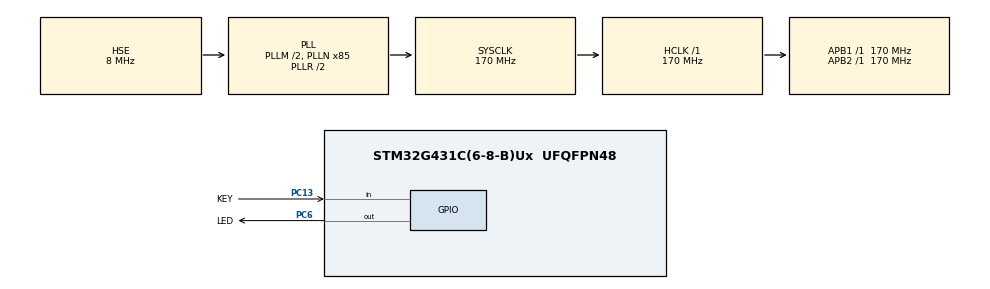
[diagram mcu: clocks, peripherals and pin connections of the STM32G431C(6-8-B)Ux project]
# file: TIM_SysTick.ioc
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Mcu.Family=STM32G4
Mcu.Name=STM32G431C(6-8-B)Ux
Mcu.Package=UFQFPN48
NVIC.PriorityGroup=NVIC_PRIORITYGROUP_4
PA13.Mode=Serial_Wire
PA13.Signal=SYS_JTMS-SWDIO
PA14.Mode=Serial_Wire
PA14.Signal=SYS_JTCK-SWCLK
PC13.GPIO_Label=KEY
PC13.GPIO_PuPd=GPIO_PULLDOWN
PC13.Signal=GPIO_Input
PC6.GPIO_Label=LED
PC6.GPIO_ModeDefaultOutputPP=GPIO_MODE_OUTPUT_PP
PC6.GPIO_Speed=GPIO_SPEED_FREQ_LOW
PC6.PinState=GPIO_PIN_RESET
PC6.Signal=GPIO_Output
PF0-OSC_IN.Mode=HSE-External-Oscillator
PF0-OSC_IN.Signal=RCC_OSC_IN
PF1-OSC_OUT.Mode=HSE-External-Oscillator
PF1-OSC_OUT.Signal=RCC_OSC_OUT
ProjectManager.HeapSize=0x200
ProjectManager.StackSize=0x400
ProjectManager.TargetToolchain=STM32CubeIDE
RCC.ADC12Freq_Value=170000000
RCC.AHBFreq_Value=170000000
RCC.APB1Freq_Value=170000000
RCC.APB1TimFreq_Value=170000000
RCC.APB2Freq_Value=170000000
RCC.APB2TimFreq_Value=170000000
RCC.CortexFreq_Value=170000000
RCC.EXTERNAL_CLOCK_VALUE=12288000
RCC.HCLKFreq_Value=170000000
RCC.HSE_VALUE=8000000
RCC.HSI48_VALUE=48000000
RCC.HSI_VALUE=16000000
RCC.LSE_VALUE=32768
RCC.PLLM=RCC_PLLM_DIV2
RCC.PLLN=85
RCC.PLLSourceVirtual=RCC_PLLSOURCE_HSE
RCC.SYSCLKFreq_VALUE=170000000
RCC.SYSCLKSource=RCC_SYSCLKSOURCE_PLLCLK
RCC.USBFreq_Value=170000000
RCC.VCOOutputFreq_Value=340000000
VP_SYS_VS_DBSignals.Mode=DisableDeadBatterySignals
board=custom

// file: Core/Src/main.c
/* USER CODE BEGIN Header */
/**
  ******************************************************************************
  * @file           : main.c
  * @brief          : Main program body
  ******************************************************************************
  * @attention
  *
  * Copyright (c) 2025 STMicroelectronics.
  * All rights reserved.
  *
  * This software is licensed under terms that can be found in the LICENSE file
  * in the root directory of this software component.
  * If no LICENSE file comes with this software, it is provided AS-IS.
  *
  ******************************************************************************
  */
/* USER CODE END Header */
#include "main.h"

/* USER CODE BEGIN PV */

uint32_t TimeResult = 0;
uint32_t TimeStart = 0;
volatile uint8_t TimeState = 0;

/* USER CODE END PV */

void SystemClock_Config(void);
static void MX_GPIO_Init(void);

int main(void)
{

  /* MCU Configuration--------------------------------------------------------*/

  /* Reset of all peripherals, Initializes the Flash interface and the Systick. */
  HAL_Init();

  /* Configure the system clock */
  SystemClock_Config();

  /* Initialize all configured peripherals */
  MX_GPIO_Init();

  /* Infinite loop */
  /* USER CODE BEGIN WHILE */
  while (1)
  {
	  if (HAL_GPIO_ReadPin(KEY_GPIO_Port, KEY_Pin) == GPIO_PIN_SET) { // If button is pressed
		  if (TimeState == 0) { // If state 0
			  TimeStart = HAL_GetTick();

			  HAL_GPIO_WritePin(LED_GPIO_Port, LED_Pin, GPIO_PIN_SET);
			  TimeState = 1;
		  } else { // TimeState == 1
			  if ((HAL_GetTick() - TimeStart) > 500) { // 0.5 seconds have passed
				  TimeResult = HAL_GetTick() - TimeStart;

				  HAL_GPIO_WritePin(LED_GPIO_Port, LED_Pin, GPIO_PIN_RESET);
				  TimeState = 0;

				  HAL_Delay(500);
			  }
		  }

	  }

    /* USER CODE END WHILE */

  }
}

void SystemClock_Config(void)
{
  RCC_OscInitTypeDef RCC_OscInitStruct = {0};
  RCC_ClkInitTypeDef RCC_ClkInitStruct = {0};

  /** Configure the main internal regulator output voltage
  */
  HAL_PWREx_ControlVoltageScaling(PWR_REGULATOR_VOLTAGE_SCALE1_BOOST);

  /** Initializes the RCC Oscillators according to the specified parameters
  * in the RCC_OscInitTypeDef structure.
  */
  RCC_OscInitStruct.OscillatorType = RCC_OSCILLATORTYPE_HSE;
  RCC_OscInitStruct.HSEState = RCC_HSE_ON;
  RCC_OscInitStruct.PLL.PLLState = RCC_PLL_ON;
  RCC_OscInitStruct.PLL.PLLSource = RCC_PLLSOURCE_HSE;
  RCC_OscInitStruct.PLL.PLLM = RCC_PLLM_DIV2;
  RCC_OscInitStruct.PLL.PLLN = 85;
  RCC_OscInitStruct.PLL.PLLP = RCC_PLLP_DIV2;
  RCC_OscInitStruct.PLL.PLLQ = RCC_PLLQ_DIV2;
  RCC_OscInitStruct.PLL.PLLR = RCC_PLLR_DIV2;
  if (HAL_RCC_OscConfig(&RCC_OscInitStruct) != HAL_OK)
  {
    Error_Handler();
  }

  /** Initializes the CPU, AHB and APB buses clocks
  */
  RCC_ClkInitStruct.ClockType = RCC_CLOCKTYPE_HCLK|RCC_CLOCKTYPE_SYSCLK
                              |RCC_CLOCKTYPE_PCLK1|RCC_CLOCKTYPE_PCLK2;
  RCC_ClkInitStruct.SYSCLKSource = RCC_SYSCLKSOURCE_PLLCLK;
  RCC_ClkInitStruct.AHBCLKDivider = RCC_SYSCLK_DIV1;
  RCC_ClkInitStruct.APB1CLKDivider = RCC_HCLK_DIV1;
  RCC_ClkInitStruct.APB2CLKDivider = RCC_HCLK_DIV1;

  if (HAL_RCC_ClockConfig(&RCC_ClkInitStruct, FLASH_LATENCY_4) != HAL_OK)
  {
    Error_Handler();
  }
}

static void MX_GPIO_Init(void)
{
  GPIO_InitTypeDef GPIO_InitStruct = {0};

  /* GPIO Ports Clock Enable */
  __HAL_RCC_GPIOC_CLK_ENABLE();
  __HAL_RCC_GPIOF_CLK_ENABLE();
  __HAL_RCC_GPIOA_CLK_ENABLE();

  /*Configure GPIO pin Output Level */
  HAL_GPIO_WritePin(LED_GPIO_Port, LED_Pin, GPIO_PIN_RESET);

  /*Configure GPIO pin : KEY_Pin */
  GPIO_InitStruct.Pin = KEY_Pin;
  GPIO_InitStruct.Mode = GPIO_MODE_INPUT;
  GPIO_InitStruct.Pull = GPIO_PULLDOWN;
  HAL_GPIO_Init(KEY_GPIO_Port, &GPIO_InitStruct);

  /*Configure GPIO pin : LED_Pin */
  GPIO_InitStruct.Pin = LED_Pin;
  GPIO_InitStruct.Mode = GPIO_MODE_OUTPUT_PP;
  GPIO_InitStruct.Pull = GPIO_NOPULL;
  GPIO_InitStruct.Speed = GPIO_SPEED_FREQ_LOW;
  HAL_GPIO_Init(LED_GPIO_Port, &GPIO_InitStruct);

}

void Error_Handler(void)
{
  __disable_irq();
  while (1)
  {
  }
}
